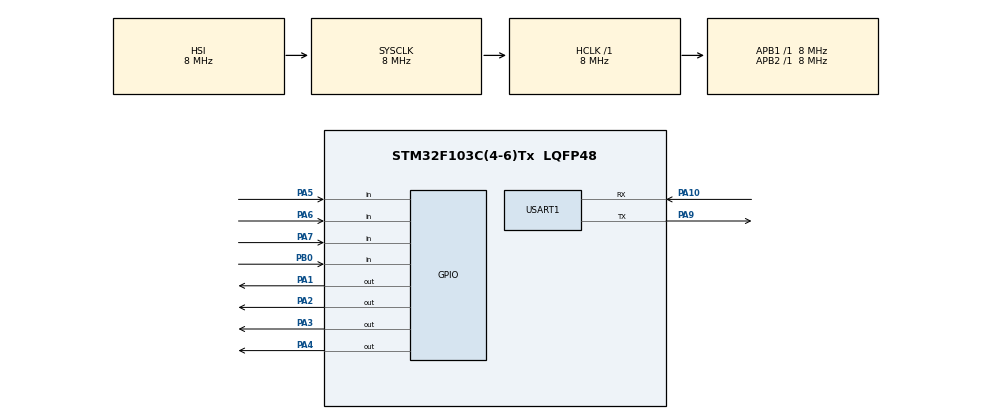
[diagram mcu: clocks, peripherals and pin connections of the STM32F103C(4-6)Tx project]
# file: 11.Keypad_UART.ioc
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Mcu.Family=STM32F1
Mcu.Name=STM32F103C(4-6)Tx
Mcu.Package=LQFP48
NVIC.PriorityGroup=NVIC_PRIORITYGROUP_4
PA1.Signal=GPIO_Output
PA10.Mode=Asynchronous
PA10.Signal=USART1_RX
PA2.Signal=GPIO_Output
PA3.Signal=GPIO_Output
PA4.Signal=GPIO_Output
PA5.Signal=GPIO_Input
PA6.Signal=GPIO_Input
PA7.Signal=GPIO_Input
PA9.Mode=Asynchronous
PA9.Signal=USART1_TX
PB0.Signal=GPIO_Input
PD0-OSC_IN.Mode=HSE-External-Oscillator
PD0-OSC_IN.Signal=RCC_OSC_IN
PD1-OSC_OUT.Mode=HSE-External-Oscillator
PD1-OSC_OUT.Signal=RCC_OSC_OUT
ProjectManager.HeapSize=0x200
ProjectManager.StackSize=0x400
ProjectManager.TargetToolchain=STM32CubeIDE
RCC.AHBFreq_Value=8000000
RCC.APB1Freq_Value=8000000
RCC.APB1TimFreq_Value=8000000
RCC.APB2Freq_Value=8000000
RCC.APB2TimFreq_Value=8000000
RCC.HCLKFreq_Value=8000000
RCC.SYSCLKFreq_VALUE=8000000
RCC.USBFreq_Value=8000000
USART1.VirtualMode=VM_ASYNC
VP_SYS_VS_ND.Mode=No_Debug
board=custom

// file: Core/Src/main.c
/* USER CODE BEGIN Header */
/**
  ******************************************************************************
  * @file           : main.c
  * @brief          : Main program body
  ******************************************************************************
  * @attention
  *
  * Copyright (c) 2025 STMicroelectronics.
  * All rights reserved.
  *
  * This software is licensed under terms that can be found in the LICENSE file
  * in the root directory of this software component.
  * If no LICENSE file comes with this software, it is provided AS-IS.
  *
  ******************************************************************************
  */
/* USER CODE END Header */
#include "main.h"

/* USER CODE BEGIN Includes */
#include "string.h"
#include "keypad_4x4.h"
/* USER CODE END Includes */

UART_HandleTypeDef huart1;

void SystemClock_Config(void);
static void MX_GPIO_Init(void);
static void MX_USART1_UART_Init(void);

int main(void)
{

  /* USER CODE BEGIN 1 */
	uint8_t key_pressed;
  /* USER CODE END 1 */

  /* MCU Configuration--------------------------------------------------------*/

  /* Reset of all peripherals, Initializes the Flash interface and the Systick. */
  HAL_Init();

  /* Configure the system clock */
  SystemClock_Config();

  /* Initialize all configured peripherals */
  MX_GPIO_Init();
  MX_USART1_UART_Init();

  /* Infinite loop */
  while (1)
  {
	  key_pressed = keypress();

	  	  if(key_pressed != '!'){

	  		  HAL_UART_Transmit(&huart1, "Pressed Key : ", strlen("Pressed Key : "), 100);
	  		  HAL_UART_Transmit(&huart1, &key_pressed, strlen(key_pressed), 100);		// P data has to be an address or data wo't transmit
	  		  HAL_UART_Transmit(&huart1, "\n\r", strlen("\n\r"), 100);
	  	  }

  }
}

void SystemClock_Config(void)
{
  RCC_OscInitTypeDef RCC_OscInitStruct = {0};
  RCC_ClkInitTypeDef RCC_ClkInitStruct = {0};

  /** Initializes the RCC Oscillators according to the specified parameters
  * in the RCC_OscInitTypeDef structure.
  */
  RCC_OscInitStruct.OscillatorType = RCC_OSCILLATORTYPE_HSI;
  RCC_OscInitStruct.HSIState = RCC_HSI_ON;
  RCC_OscInitStruct.HSICalibrationValue = RCC_HSICALIBRATION_DEFAULT;
  RCC_OscInitStruct.PLL.PLLState = RCC_PLL_NONE;
  if (HAL_RCC_OscConfig(&RCC_OscInitStruct) != HAL_OK)
  {
    Error_Handler();
  }

  /** Initializes the CPU, AHB and APB buses clocks
  */
  RCC_ClkInitStruct.ClockType = RCC_CLOCKTYPE_HCLK|RCC_CLOCKTYPE_SYSCLK
                              |RCC_CLOCKTYPE_PCLK1|RCC_CLOCKTYPE_PCLK2;
  RCC_ClkInitStruct.SYSCLKSource = RCC_SYSCLKSOURCE_HSI;
  RCC_ClkInitStruct.AHBCLKDivider = RCC_SYSCLK_DIV1;
  RCC_ClkInitStruct.APB1CLKDivider = RCC_HCLK_DIV1;
  RCC_ClkInitStruct.APB2CLKDivider = RCC_HCLK_DIV1;

  if (HAL_RCC_ClockConfig(&RCC_ClkInitStruct, FLASH_LATENCY_0) != HAL_OK)
  {
    Error_Handler();
  }
}

static void MX_USART1_UART_Init(void)
{

  huart1.Instance = USART1;
  huart1.Init.BaudRate = 115200;
  huart1.Init.WordLength = UART_WORDLENGTH_8B;
  huart1.Init.StopBits = UART_STOPBITS_1;
  huart1.Init.Parity = UART_PARITY_NONE;
  huart1.Init.Mode = UART_MODE_TX_RX;
  huart1.Init.HwFlowCtl = UART_HWCONTROL_NONE;
  huart1.Init.OverSampling = UART_OVERSAMPLING_16;
  if (HAL_UART_Init(&huart1) != HAL_OK)
  {
    Error_Handler();
  }

}

static void MX_GPIO_Init(void)
{
  GPIO_InitTypeDef GPIO_InitStruct = {0};

  /* GPIO Ports Clock Enable */
  __HAL_RCC_GPIOD_CLK_ENABLE();
  __HAL_RCC_GPIOA_CLK_ENABLE();
  __HAL_RCC_GPIOB_CLK_ENABLE();

  /*Configure GPIO pin Output Level */
  HAL_GPIO_WritePin(GPIOA, GPIO_PIN_1|GPIO_PIN_2|GPIO_PIN_3|GPIO_PIN_4, GPIO_PIN_RESET);

  /*Configure GPIO pins : PA1 PA2 PA3 PA4 */
  GPIO_InitStruct.Pin = GPIO_PIN_1|GPIO_PIN_2|GPIO_PIN_3|GPIO_PIN_4;
  GPIO_InitStruct.Mode = GPIO_MODE_OUTPUT_PP;
  GPIO_InitStruct.Pull = GPIO_NOPULL;
  GPIO_InitStruct.Speed = GPIO_SPEED_FREQ_LOW;
  HAL_GPIO_Init(GPIOA, &GPIO_InitStruct);

  /*Configure GPIO pins : PA5 PA6 PA7 */
  GPIO_InitStruct.Pin = GPIO_PIN_5|GPIO_PIN_6|GPIO_PIN_7;
  GPIO_InitStruct.Mode = GPIO_MODE_INPUT;
  GPIO_InitStruct.Pull = GPIO_NOPULL;
  HAL_GPIO_Init(GPIOA, &GPIO_InitStruct);

  /*Configure GPIO pin : PB0 */
  GPIO_InitStruct.Pin = GPIO_PIN_0;
  GPIO_InitStruct.Mode = GPIO_MODE_INPUT;
  GPIO_InitStruct.Pull = GPIO_NOPULL;
  HAL_GPIO_Init(GPIOB, &GPIO_InitStruct);

}

void Error_Handler(void)
{
  __disable_irq();
  while (1)
  {
  }
}
